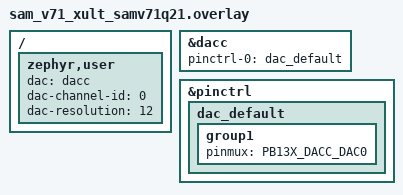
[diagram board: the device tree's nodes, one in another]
/ {
	zephyr,user {
		dac = <&dacc>;
		dac-channel-id = <0>;
		dac-resolution = <12>;
	};
};

&dacc {
	pinctrl-0 = <&dac_default>;
	pinctrl-names = "default";
	status = "okay";
};

&pinctrl {
	dac_default: dac_default {
		group1 {
			pinmux = <PB13X_DACC_DAC0>;
		};
	};
};
